# WBZ451 register map
Vendor: Microchip
Registers are 32-bit, read-write, reset 0x0 unless marked. A register's access mark holds for its fields unless they carry their own. Addresses are absolute, and some are shared; only a register's first bit layout is shown; [hi:lo] are bit positions; {n}, {i} and the like mark numbered series.

## GPIOA
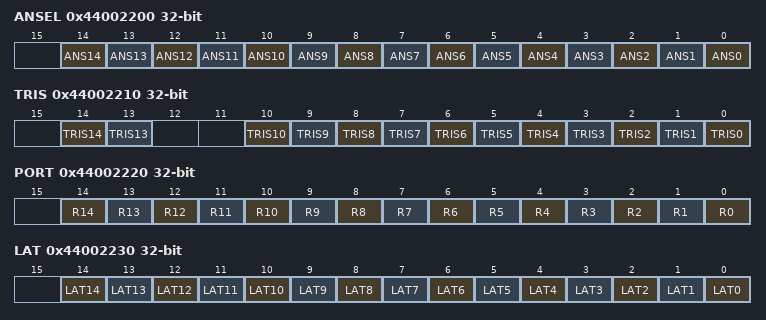
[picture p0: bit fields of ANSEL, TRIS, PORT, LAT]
0x44002200 ANSEL
  [n] ANS{n} (n=0..14)
0x44002204 ANSELCLR
0x44002208 ANSELSET
0x4400220C ANSELINV
0x44002210 TRIS
  [14] TRIS14, [13] TRIS13, [n] TRIS{n} (n=0..10)
0x44002214 TRISCLR
0x44002218 TRISSET
0x4400221C TRISINV
0x44002220 PORT
  [n] R{n} (n=0..14)
0x44002224 PORTCLR
0x44002228 PORTSET
0x4400222C PORTINV
0x44002230 LAT
  [n] LAT{n} (n=0..14)
0x44002234 LATCLR
0x44002238 LATSET
0x4400223C LATINV
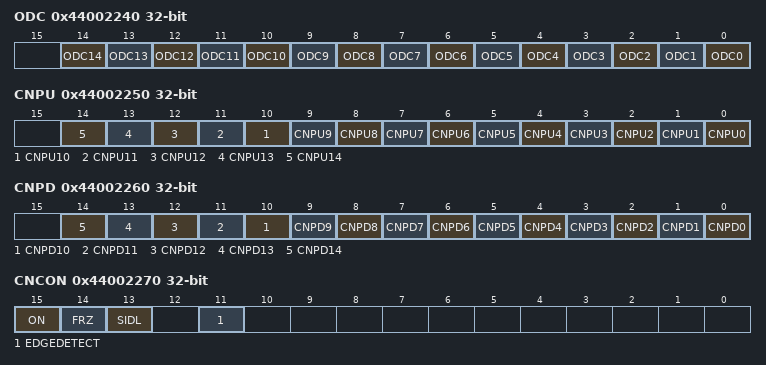
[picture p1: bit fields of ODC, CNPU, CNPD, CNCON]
0x44002240 ODC
  [n] ODC{n} (n=0..14)
0x44002244 ODCCLR
0x44002248 ODCSET
0x4400224C ODCINV
0x44002250 CNPU
  [n] CNPU{n} (n=0..14)
0x44002254 CNPUCLR
0x44002258 CNPUSET
0x4400225C CNPUINV
0x44002260 CNPD
  [n] CNPD{n} (n=0..14)
0x44002264 CNPDCLR
0x44002268 CNPDSET
0x4400226C CNPDINV
0x44002270 CNCON
  [15] ON, [14] FRZ, [13] SIDL, [11] EDGEDETECT
0x44002274 CNCONCLR
0x44002278 CNCONSET
0x4400227C CNCONINV
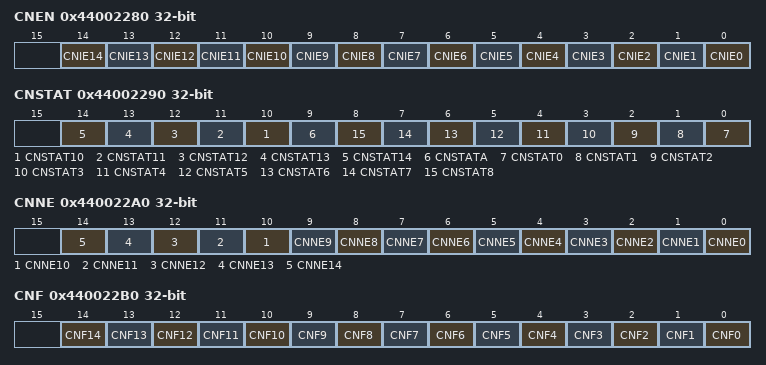
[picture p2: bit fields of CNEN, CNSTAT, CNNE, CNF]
0x44002280 CNEN
  [n] CNIE{n} (n=0..14)
0x44002284 CNENCLR
0x44002288 CNENSET
0x4400228C CNENINV
0x44002290 CNSTAT
  [n] CNSTAT{n} (n=10..14), [9] CNSTATA, [n] CNSTAT{n} (n=0..8)
0x44002294 CNSTATCLR
0x44002298 CNSTATSET
0x4400229C CNSTATINV
0x440022A0 CNNE
  [n] CNNE{n} (n=0..14)
0x440022A4 CNNECLR
0x440022A8 CNNESET
0x440022AC CNNEINV
0x440022B0 CNF
  [n] CNF{n} (n=0..14)
0x440022B4 CNFCLR
0x440022B8 CNFSET
0x440022BC CNFINV
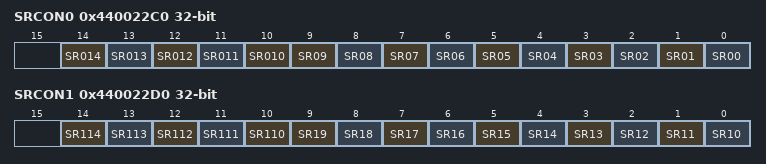
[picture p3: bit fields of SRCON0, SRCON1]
0x440022C0 SRCON0
  [n] SR{n:03} (n=10..14), [n] SR{n:02} (n=0..9)
0x440022C4 SRCON0CLR
0x440022C8 SRCON0SET
0x440022CC SRCON0INV
0x440022D0 SRCON1
  [n-100] SR{n} (n=110..114), [n-10] SR{n} (n=10..19)
0x440022D4 SRCON1CLR
0x440022D8 SRCON1SET
0x440022DC SRCON1INV

## GPIOB
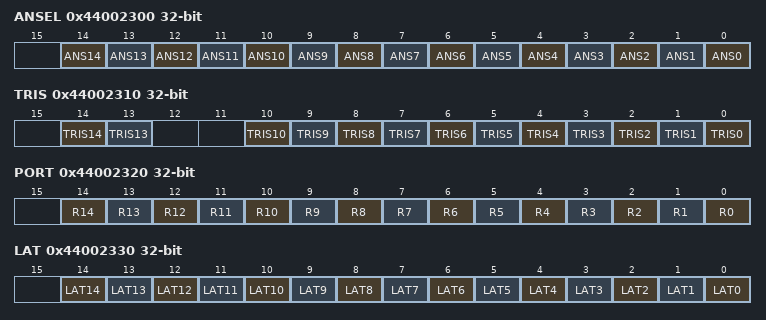
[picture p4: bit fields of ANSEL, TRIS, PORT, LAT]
0x44002300 ANSEL
  [n] ANS{n} (n=0..14)
0x44002304 ANSELCLR
0x44002308 ANSELSET
0x4400230C ANSELINV
0x44002310 TRIS
  [14] TRIS14, [13] TRIS13, [n] TRIS{n} (n=0..10)
0x44002314 TRISCLR
0x44002318 TRISSET
0x4400231C TRISINV
0x44002320 PORT
  [n] R{n} (n=0..14)
0x44002324 PORTCLR
0x44002328 PORTSET
0x4400232C PORTINV
0x44002330 LAT
  [n] LAT{n} (n=0..14)
0x44002334 LATCLR
0x44002338 LATSET
0x4400233C LATINV
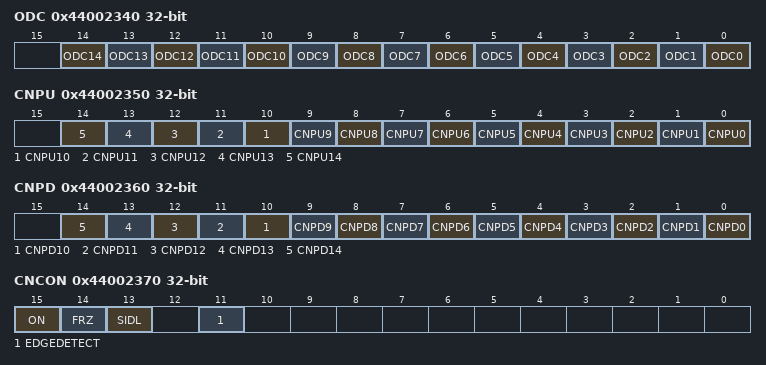
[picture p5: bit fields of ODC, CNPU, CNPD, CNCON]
0x44002340 ODC
  [n] ODC{n} (n=0..14)
0x44002344 ODCCLR
0x44002348 ODCSET
0x4400234C ODCINV
0x44002350 CNPU
  [n] CNPU{n} (n=0..14)
0x44002354 CNPUCLR
0x44002358 CNPUSET
0x4400235C CNPUINV
0x44002360 CNPD
  [n] CNPD{n} (n=0..14)
0x44002364 CNPDCLR
0x44002368 CNPDSET
0x4400236C CNPDINV
0x44002370 CNCON
  [15] ON, [14] FRZ, [13] SIDL, [11] EDGEDETECT
0x44002374 CNCONCLR
0x44002378 CNCONSET
0x4400237C CNCONINV
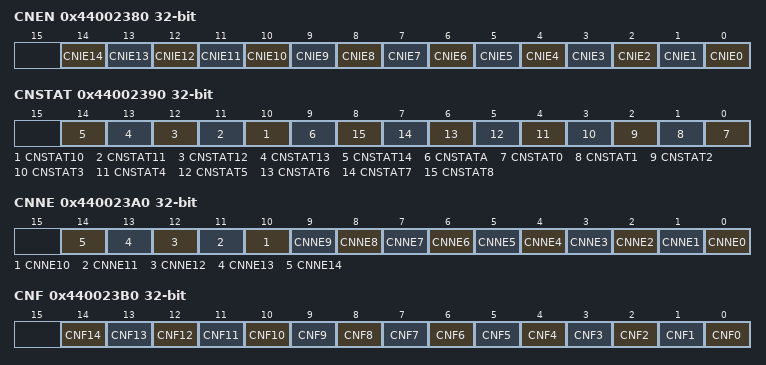
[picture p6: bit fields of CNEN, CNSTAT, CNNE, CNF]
0x44002380 CNEN
  [n] CNIE{n} (n=0..14)
0x44002384 CNENCLR
0x44002388 CNENSET
0x4400238C CNENINV
0x44002390 CNSTAT
  [n] CNSTAT{n} (n=10..14), [9] CNSTATA, [n] CNSTAT{n} (n=0..8)
0x44002394 CNSTATCLR
0x44002398 CNSTATSET
0x4400239C CNSTATINV
0x440023A0 CNNE
  [n] CNNE{n} (n=0..14)
0x440023A4 CNNECLR
0x440023A8 CNNESET
0x440023AC CNNEINV
0x440023B0 CNF
  [n] CNF{n} (n=0..14)
0x440023B4 CNFCLR
0x440023B8 CNFSET
0x440023BC CNFINV
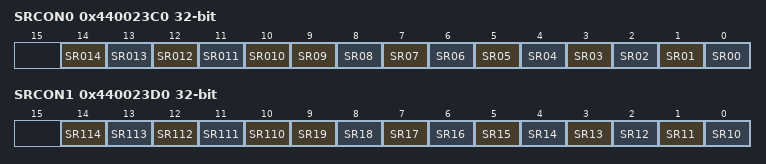
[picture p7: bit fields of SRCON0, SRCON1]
0x440023C0 SRCON0
  [n] SR{n:03} (n=10..14), [n] SR{n:02} (n=0..9)
0x440023C4 SRCON0CLR
0x440023C8 SRCON0SET
0x440023CC SRCON0INV
0x440023D0 SRCON1
  [n-100] SR{n} (n=110..114), [n-10] SR{n} (n=10..19)
0x440023D4 SRCON1CLR
0x440023D8 SRCON1SET
0x440023DC SRCON1INV

## PCHE
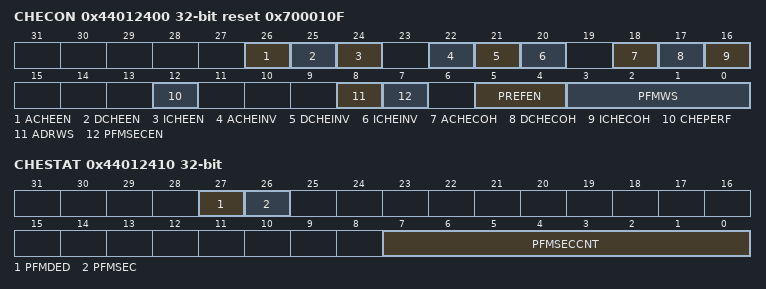
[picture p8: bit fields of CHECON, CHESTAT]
0x44012400 CHECON reset 0x700010F
  [26] ACHEEN, [25] DCHEEN, [24] ICHEEN, [22] ACHEINV, [21] DCHEINV, [20] ICHEINV, [18] ACHECOH, [17] DCHECOH, [16] ICHECOH, [12] CHEPERF, [8] ADRWS, [7] PFMSECEN, [5:4] PREFEN, [3:0] PFMWS
0x44012410 CHESTAT
  [27] PFMDED, [26] PFMSEC, [7:0] PFMSECCNT
0x44012420 CHEHIT
0x44012430 CHEMIS

## PMU
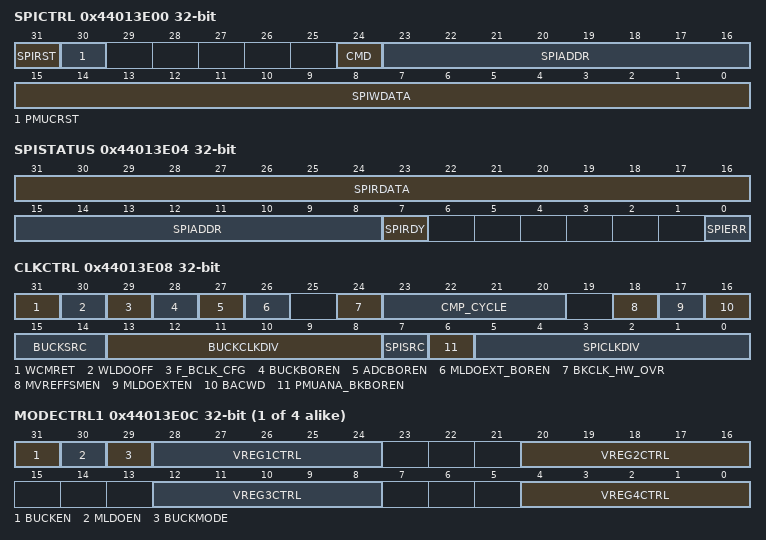
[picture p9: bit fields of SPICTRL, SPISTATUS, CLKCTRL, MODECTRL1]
0x44013E00 SPICTRL
  [31] SPIRST, [30] PMUCRST, [24] CMD, [23:16] SPIADDR, [15:0] SPIWDATA
0x44013E04 SPISTATUS
  [31:16] SPIRDATA, [15:8] SPIADDR, [7] SPIRDY, [0] SPIERR
0x44013E08 CLKCTRL
  [31] WCMRET, [30] WLDOOFF, [29] F_BCLK_CFG, [28] BUCKBOREN, [27] ADCBOREN, [26] MLDOEXT_BOREN, [24] BKCLK_HW_OVR, [23:20] CMP_CYCLE, [18] MVREFFSMEN, [17] MLDOEXTEN, [16] BACWD, [15:14] BUCKSRC, [13:8] BUCKCLKDIV, [7] SPISRC, [6] PMUANA_BKBOREN, [5:0] SPICLKDIV
{0x44013E08+4i} MODECTRL{i} (i=1..4)
  [31] BUCKEN, [30] MLDOEN, [29] BUCKMODE, [36-8n:32-8n] VREG{n}CTRL (n=1..4)
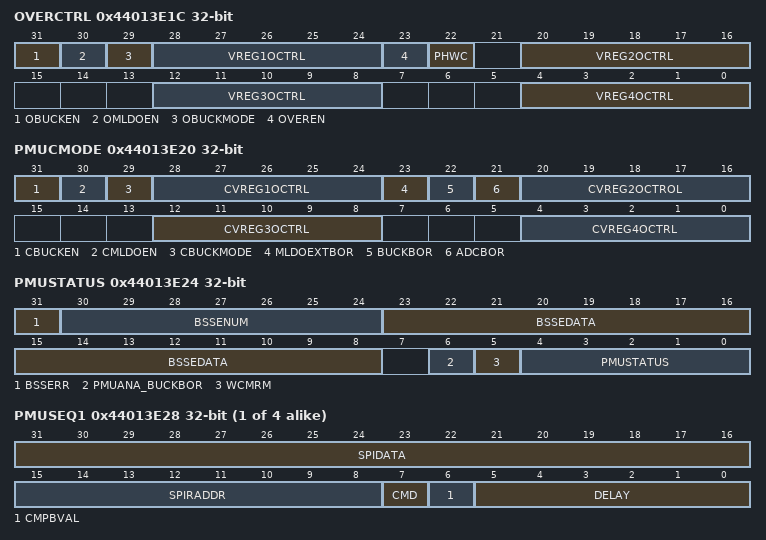
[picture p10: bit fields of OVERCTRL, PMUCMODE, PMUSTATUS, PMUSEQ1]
0x44013E1C OVERCTRL
  [31] OBUCKEN, [30] OMLDOEN, [29] OBUCKMODE, [36-8n:32-8n] VREG{n}OCTRL (n=1..4), [23] OVEREN, [22] PHWC
0x44013E20 PMUCMODE
  [31] CBUCKEN, [30] CMLDOEN, [29] CBUCKMODE, [28:24] CVREG1OCTRL, [23] MLDOEXTBOR, [22] BUCKBOR, [21] ADCBOR, [20:16] CVREG2OCTROL, [12:8] CVREG3OCTRL, [4:0] CVREG4OCTRL
0x44013E24 PMUSTATUS
  [31] BSSERR, [30:24] BSSENUM, [23:8] BSSEDATA, [6] PMUANA_BUCKBOR, [5] WCMRM, [4:0] PMUSTATUS
{0x44013E24+4i} PMUSEQ{i} (i=1..4)
  [31:16] SPIDATA, [15:8] SPIRADDR, [7] CMD, [6] CMPBVAL, [5:0] DELAY
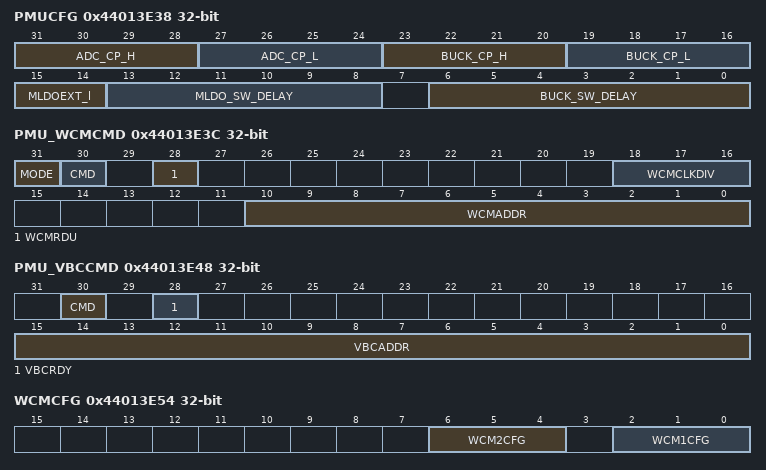
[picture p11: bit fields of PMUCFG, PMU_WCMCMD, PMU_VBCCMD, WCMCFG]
0x44013E38 PMUCFG
  [31:28] ADC_CP_H, [27:24] ADC_CP_L, [23:20] BUCK_CP_H, [19:16] BUCK_CP_L, [15:14] MLDOEXT_l, [13:8] MLDO_SW_DELAY, [6:0] BUCK_SW_DELAY
0x44013E3C PMU_WCMCMD
  [31] MODE, [30] CMD, [28] WCMRDU, [18:16] WCMCLKDIV, [10:0] WCMADDR
0x44013E40 PMU_WCMWDATA
0x44013E44 PMU_WCMRDATA
0x44013E48 PMU_VBCCMD
  [30] CMD, [28] VBCRDY, [15:0] VBCADDR
0x44013E4C PMU_VBCWDATA
0x44013E50 PMU_VBCRDATA
0x44013E54 WCMCFG
  [6:4] WCM2CFG, [2:0] WCM1CFG
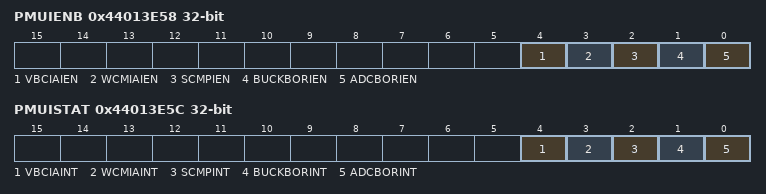
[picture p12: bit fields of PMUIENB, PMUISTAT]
0x44013E58 PMUIENB
  [4] VBCIAIEN, [3] WCMIAIEN, [2] SCMPIEN, [1] BUCKBORIEN, [0] ADCBORIEN
0x44013E5C PMUISTAT
  [4] VBCIAINT, [3] WCMIAINT, [2] SCMPINT, [1] BUCKBORINT, [0] ADCBORINT
